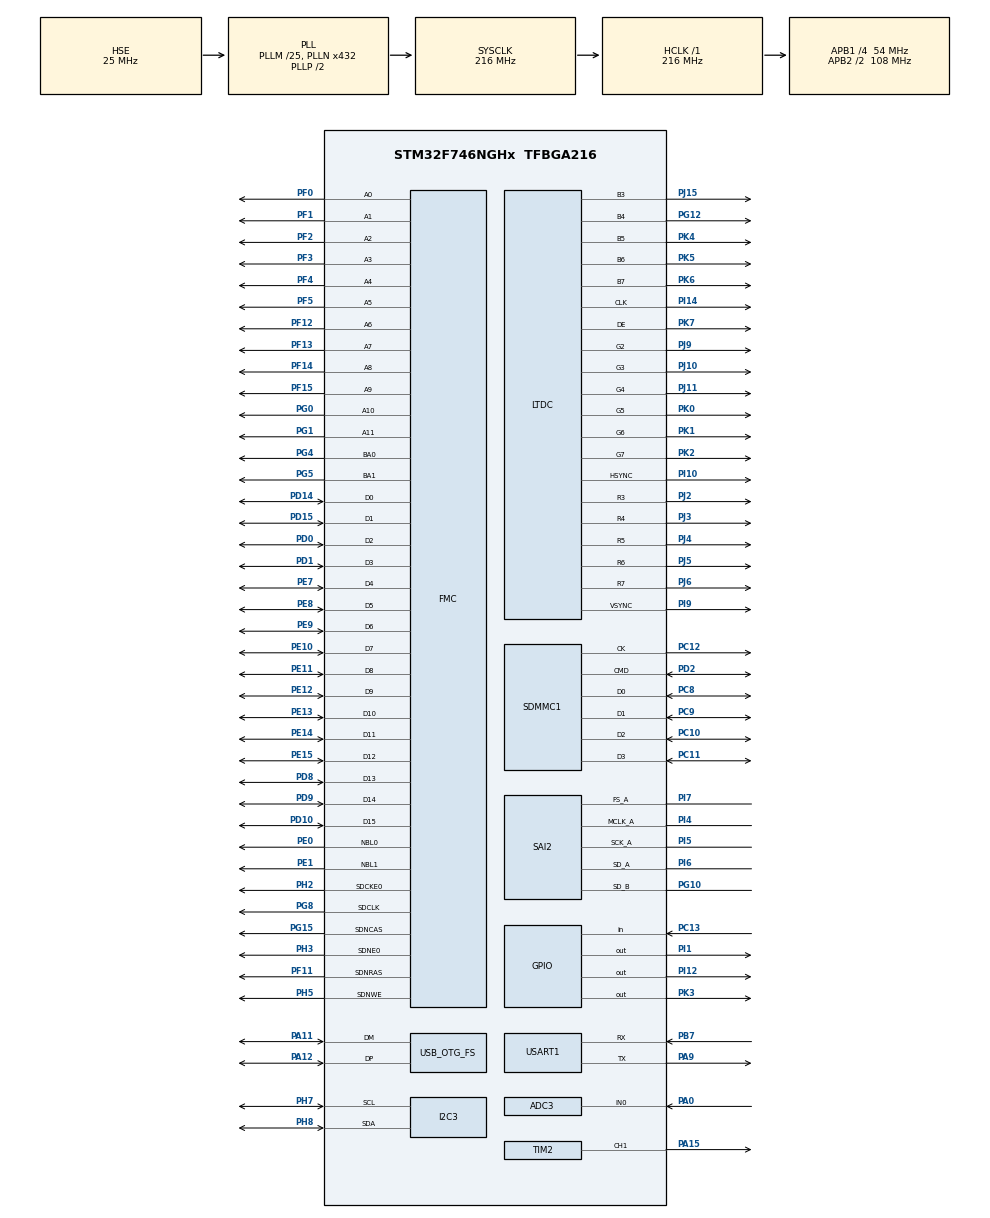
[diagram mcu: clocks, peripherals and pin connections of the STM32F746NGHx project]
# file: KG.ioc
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ADC3.Channel-1\#ChannelRegularConversion=ADC_CHANNEL_0
ADC3.DMAContinuousRequests=ENABLE
ADC3.ExternalTrigConv=ADC_EXTERNALTRIGCONV_T2_CC2
ADC3.NbrOfConversion=1
ADC3.NbrOfConversionFlag=1
ADC3.Rank-1\#ChannelRegularConversion=1
ADC3.SamplingTime-1\#ChannelRegularConversion=ADC_SAMPLETIME_3CYCLES
Dma.ADC3.4.Direction=DMA_PERIPH_TO_MEMORY
Dma.ADC3.4.FIFOMode=DMA_FIFOMODE_DISABLE
Dma.ADC3.4.Instance=DMA2_Stream0
Dma.ADC3.4.MemDataAlignment=DMA_MDATAALIGN_HALFWORD
Dma.ADC3.4.MemInc=DMA_MINC_ENABLE
Dma.ADC3.4.Mode=DMA_CIRCULAR
Dma.ADC3.4.PeriphDataAlignment=DMA_PDATAALIGN_HALFWORD
Dma.ADC3.4.PeriphInc=DMA_PINC_DISABLE
Dma.ADC3.4.Priority=DMA_PRIORITY_LOW
Dma.Request0=SDMMC1_RX
Dma.Request1=SDMMC1_TX
Dma.Request2=SAI2_A
Dma.Request3=SAI2_B
Dma.Request4=ADC3
Dma.SAI2_A.2.Direction=DMA_MEMORY_TO_PERIPH
Dma.SAI2_A.2.FIFOMode=DMA_FIFOMODE_DISABLE
Dma.SAI2_A.2.Instance=DMA2_Stream4
Dma.SAI2_A.2.MemDataAlignment=DMA_MDATAALIGN_HALFWORD
Dma.SAI2_A.2.MemInc=DMA_MINC_ENABLE
Dma.SAI2_A.2.Mode=DMA_CIRCULAR
Dma.SAI2_A.2.PeriphDataAlignment=DMA_PDATAALIGN_HALFWORD
Dma.SAI2_A.2.PeriphInc=DMA_PINC_DISABLE
Dma.SAI2_A.2.Priority=DMA_PRIORITY_LOW
Dma.SAI2_B.3.Direction=DMA_PERIPH_TO_MEMORY
Dma.SAI2_B.3.FIFOMode=DMA_FIFOMODE_DISABLE
Dma.SAI2_B.3.Instance=DMA2_Stream7
Dma.SAI2_B.3.MemDataAlignment=DMA_MDATAALIGN_HALFWORD
Dma.SAI2_B.3.MemInc=DMA_MINC_ENABLE
Dma.SAI2_B.3.Mode=DMA_CIRCULAR
Dma.SAI2_B.3.PeriphDataAlignment=DMA_PDATAALIGN_HALFWORD
Dma.SAI2_B.3.PeriphInc=DMA_PINC_DISABLE
Dma.SAI2_B.3.Priority=DMA_PRIORITY_LOW
Dma.SDMMC1_RX.0.Direction=DMA_PERIPH_TO_MEMORY
Dma.SDMMC1_RX.0.FIFOMode=DMA_FIFOMODE_ENABLE
Dma.SDMMC1_RX.0.FIFOThreshold=DMA_FIFO_THRESHOLD_FULL
Dma.SDMMC1_RX.0.Instance=DMA2_Stream3
Dma.SDMMC1_RX.0.MemBurst=DMA_MBURST_INC4
Dma.SDMMC1_RX.0.MemDataAlignment=DMA_MDATAALIGN_WORD
Dma.SDMMC1_RX.0.MemInc=DMA_MINC_ENABLE
Dma.SDMMC1_RX.0.Mode=DMA_PFCTRL
Dma.SDMMC1_RX.0.PeriphBurst=DMA_PBURST_INC4
Dma.SDMMC1_RX.0.PeriphDataAlignment=DMA_PDATAALIGN_WORD
Dma.SDMMC1_RX.0.PeriphInc=DMA_PINC_DISABLE
Dma.SDMMC1_RX.0.Priority=DMA_PRIORITY_LOW
Dma.SDMMC1_TX.1.Direction=DMA_MEMORY_TO_PERIPH
Dma.SDMMC1_TX.1.FIFOMode=DMA_FIFOMODE_ENABLE
Dma.SDMMC1_TX.1.FIFOThreshold=DMA_FIFO_THRESHOLD_FULL
Dma.SDMMC1_TX.1.Instance=DMA2_Stream6
Dma.SDMMC1_TX.1.MemBurst=DMA_MBURST_INC4
Dma.SDMMC1_TX.1.MemDataAlignment=DMA_MDATAALIGN_WORD
Dma.SDMMC1_TX.1.MemInc=DMA_MINC_ENABLE
Dma.SDMMC1_TX.1.Mode=DMA_PFCTRL
Dma.SDMMC1_TX.1.PeriphBurst=DMA_PBURST_INC4
Dma.SDMMC1_TX.1.PeriphDataAlignment=DMA_PDATAALIGN_WORD
Dma.SDMMC1_TX.1.PeriphInc=DMA_PINC_DISABLE
Dma.SDMMC1_TX.1.Priority=DMA_PRIORITY_LOW
FATFS.BSP.number=1
FATFS.USE_DMA_CODE_SD=1
FATFS._LFN_UNICODE=0
FATFS._STRF_ENCODE=0
FATFS._USE_LFN=0
FATFS0.BSP.STBoard=false
FATFS0.BSP.api=Unknown
FATFS0.BSP.instance=PC13
FATFS0.BSP.ip=GPIO
FATFS0.BSP.mode=Input
FATFS0.BSP.name=Detect_SDIO
FATFS0.BSP.solution=PC13
FMC.CASLatency1=FMC_SDRAM_CAS_LATENCY_3
FMC.ExitSelfRefreshDelay1=7
FMC.LoadToActiveDelay1=2
FMC.RCDDelay1=2
FMC.RPDelay1=2
FMC.RPDelay2=2
FMC.RowCycleDelay1=7
FMC.RowCycleDelay2=7
FMC.SelfRefreshTime1=4
FMC.WriteRecoveryTime1=3
I2C3.Timing=0x20404768
LTDC.ActiveH=272
LTDC.ActiveW=480
LTDC.Alpha_L0=255
LTDC.FBStartAdress_L0=0xC0000000
LTDC.HBP=43
LTDC.HFP=8
LTDC.HSync=1
LTDC.ImageHeight_L0=272
LTDC.ImageWidth_L0=480
LTDC.Layers=0
LTDC.PixelFormat_L0=LTDC_PIXEL_FORMAT_RGB565
LTDC.VBP=12
LTDC.VFP=4
LTDC.VSync=10
LTDC.WindowX1_L0=480
LTDC.WindowY1_L0=272
Mcu.Family=STM32F7
Mcu.Name=STM32F746NGHx
Mcu.Package=TFBGA216
NVIC.DMA2_Stream0_IRQn=true\:0\:0\:false\:false\:true\:false\:true\:true
NVIC.DMA2_Stream3_IRQn=true\:6\:0\:true\:false\:true\:false\:true\:true
NVIC.DMA2_Stream4_IRQn=true\:0\:0\:true\:false\:true\:false\:true\:true
NVIC.DMA2_Stream6_IRQn=true\:6\:0\:true\:false\:true\:false\:true\:true
NVIC.DMA2_Stream7_IRQn=true\:0\:0\:false\:false\:true\:false\:true\:true
NVIC.I2C3_EV_IRQn=true\:0\:0\:false\:false\:true\:true\:true\:true
NVIC.OTG_FS_IRQn=true\:7\:0\:true\:false\:true\:false\:true\:true
NVIC.PriorityGroup=NVIC_PRIORITYGROUP_4
NVIC.SAI2_IRQn=true\:0\:0\:false\:false\:true\:true\:true\:true
NVIC.SDMMC1_IRQn=true\:5\:0\:true\:false\:true\:true\:true\:true
NVIC.USART1_IRQn=true\:0\:0\:false\:false\:true\:true\:true\:true
PA0/WKUP.Signal=ADCx_IN0
PA11.Mode=Device_Only
PA11.Signal=USB_OTG_FS_DM
PA12.Mode=Device_Only
PA12.Signal=USB_OTG_FS_DP
PA13.Mode=Trace_Asynchronous_SW
PA13.Signal=SYS_JTMS-SWDIO
PA14.Mode=Trace_Asynchronous_SW
PA14.Signal=SYS_JTCK-SWCLK
PA15.Signal=S_TIM2_CH1_ETR
PA9.Mode=Asynchronous
PA9.Signal=USART1_TX
PB3.Mode=Trace_Asynchronous_SW
PB3.Signal=SYS_JTDO-SWO
PB7.Mode=Asynchronous
PB7.Signal=USART1_RX
PC10.Mode=SD_4_bits_Wide_bus
PC10.Signal=SDMMC1_D2
PC11.Mode=SD_4_bits_Wide_bus
PC11.Signal=SDMMC1_D3
PC12.Mode=SD_4_bits_Wide_bus
PC12.Signal=SDMMC1_CK
PC13.Signal=GPIO_Input
PC14/OSC32_IN.Mode=LSE-External-Oscillator
PC14/OSC32_IN.Signal=RCC_OSC32_IN
PC15/OSC32_OUT.Mode=LSE-External-Oscillator
PC15/OSC32_OUT.Signal=RCC_OSC32_OUT
PC8.Mode=SD_4_bits_Wide_bus
PC8.Signal=SDMMC1_D0
PC9.Mode=SD_4_bits_Wide_bus
PC9.Signal=SDMMC1_D1
PD0.Signal=FMC_D2_DA2
PD1.Signal=FMC_D3_DA3
PD10.Signal=FMC_D15_DA15
PD14.Signal=FMC_D0_DA0
PD15.Signal=FMC_D1_DA1
PD2.Mode=SD_4_bits_Wide_bus
PD2.Signal=SDMMC1_CMD
PD8.Signal=FMC_D13_DA13
PD9.Signal=FMC_D14_DA14
PE0.Signal=FMC_NBL0
PE1.Signal=FMC_NBL1
PE10.Signal=FMC_D7_DA7
PE11.Signal=FMC_D8_DA8
PE12.Signal=FMC_D9_DA9
PE13.Signal=FMC_D10_DA10
PE14.Signal=FMC_D11_DA11
PE15.Signal=FMC_D12_DA12
PE7.Signal=FMC_D4_DA4
PE8.Signal=FMC_D5_DA5
PE9.Signal=FMC_D6_DA6
PF0.Signal=FMC_A0
PF1.Signal=FMC_A1
PF11.Signal=FMC_SDNRAS
PF12.Signal=FMC_A6
PF13.Signal=FMC_A7
PF14.Signal=FMC_A8
PF15.Signal=FMC_A9
PF2.Signal=FMC_A2
PF3.Signal=FMC_A3
PF4.Signal=FMC_A4
PF5.Signal=FMC_A5
PG0.Signal=FMC_A10
PG1.Signal=FMC_A11
PG10.Mode=SAI_B_SyncSlave
PG10.Signal=SAI2_SD_B
PG12.Mode=RGB565
PG12.Signal=LTDC_B4
PG15.Signal=FMC_SDNCAS
PG4.Signal=FMC_A14_BA0
PG5.Signal=FMC_A15_BA1
PG8.Signal=FMC_SDCLK
PH0/OSC_IN.Mode=HSE-External-Oscillator
PH0/OSC_IN.Signal=RCC_OSC_IN
PH1/OSC_OUT.Mode=HSE-External-Oscillator
PH1/OSC_OUT.Signal=RCC_OSC_OUT
PH2.Mode=SdramChipSelect1_1
PH2.Signal=FMC_SDCKE0
PH3.Mode=SdramChipSelect1_1
PH3.Signal=FMC_SDNE0
PH5.Signal=FMC_SDNWE
PH7.Mode=I2C
PH7.Signal=I2C3_SCL
PH8.Mode=I2C
PH8.Signal=I2C3_SDA
PI1.Signal=GPIO_Output
PI10.Mode=RGB565
PI10.Signal=LTDC_HSYNC
PI12.PinState=GPIO_PIN_SET
PI12.Signal=GPIO_Output
PI14.Mode=RGB565
PI14.Signal=LTDC_CLK
PI4.Mode=SAI_A_MasterWithClock
PI4.Signal=SAI2_MCLK_A
PI5.Mode=SAI_A_MasterWithClock
PI5.Signal=SAI2_SCK_A
PI6.Mode=SAI_A_MasterWithClock
PI6.Signal=SAI2_SD_A
PI7.Mode=SAI_A_MasterWithClock
PI7.Signal=SAI2_FS_A
PI9.Mode=RGB565
PI9.Signal=LTDC_VSYNC
PJ10.Mode=RGB565
PJ10.Signal=LTDC_G3
PJ11.Mode=RGB565
PJ11.Signal=LTDC_G4
PJ15.Mode=RGB565
PJ15.Signal=LTDC_B3
PJ2.Mode=RGB565
PJ2.Signal=LTDC_R3
PJ3.Mode=RGB565
PJ3.Signal=LTDC_R4
PJ4.Mode=RGB565
PJ4.Signal=LTDC_R5
PJ5.Mode=RGB565
PJ5.Signal=LTDC_R6
PJ6.Mode=RGB565
PJ6.Signal=LTDC_R7
PJ9.Mode=RGB565
PJ9.Signal=LTDC_G2
PK0.Mode=RGB565
PK0.Signal=LTDC_G5
PK1.Mode=RGB565
PK1.Signal=LTDC_G6
PK2.Mode=RGB565
PK2.Signal=LTDC_G7
PK3.PinState=GPIO_PIN_SET
PK3.Signal=GPIO_Output
PK4.Mode=RGB565
PK4.Signal=LTDC_B5
PK5.Mode=RGB565
PK5.Signal=LTDC_B6
PK6.Mode=RGB565
PK6.Signal=LTDC_B7
PK7.Mode=RGB565
PK7.Signal=LTDC_DE
ProjectManager.HeapSize=0x1000
ProjectManager.StackSize=0x1000
ProjectManager.TargetToolchain=MDK-ARM V5.32
RCC.AHBFreq_Value=216000000
RCC.APB1CLKDivider=RCC_HCLK_DIV4
RCC.APB1Freq_Value=54000000
RCC.APB1TimFreq_Value=108000000
RCC.APB2CLKDivider=RCC_HCLK_DIV2
RCC.APB2Freq_Value=108000000
RCC.APB2TimFreq_Value=216000000
RCC.CortexFreq_Value=216000000
RCC.HCLKFreq_Value=216000000
RCC.HSE_VALUE=25000000
RCC.HSI_VALUE=16000000
RCC.PLLI2SN=344
RCC.PLLI2SQ=7
RCC.PLLM=25
RCC.PLLN=432
RCC.PLLQ=9
RCC.PLLSAIN=200
RCC.PLLSAIR=5
RCC.PLLSAIRDiv=RCC_PLLSAIDIVR_4
RCC.RTCClockSelection=RCC_RTCCLKSOURCE_LSE
RCC.SAI2CLockSelection=RCC_SAI2CLKSOURCE_PLLI2S
RCC.SDMMCClockSelection=RCC_SDMMC1CLKSOURCE_CLK48
RCC.SYSCLKFreq_VALUE=216000000
RCC.SYSCLKSource=RCC_SYSCLKSOURCE_PLLCLK
RCC.USBFreq_Value=48000000
RCC.VCOOutputFreq_Value=432000000
RTC.Date=17
RTC.Hours=12
RTC.Minutes=4
RTC.Month=RTC_MONTH_OCTOBER
RTC.Seconds=33
RTC.Year=22
SAI2.ActiveFrameLength-SAI_A_MasterWithClock=32
SAI2.ActiveFrameLength-SAI_B_SyncSlave=32
SAI2.AudioFrequency-SAI_A_MasterWithClock=SAI_AUDIO_FREQUENCY_48K
SAI2.ClockStrobing-SAI_A_MasterWithClock=SAI_CLOCKSTROBING_RISINGEDGE
SAI2.DataSize-SAI_A_MasterWithClock=SAI_DATASIZE_16
SAI2.DataSize-SAI_B_SyncSlave=SAI_DATASIZE_16
SAI2.ErrorAudioFreq-SAI_A_MasterWithClock=-0.01 %
SAI2.FIFOThreshold-SAI_A_MasterWithClock=SAI_FIFOTHRESHOLD_1QF
SAI2.FIFOThreshold-SAI_B_SyncSlave=SAI_FIFOTHRESHOLD_1QF
SAI2.FSDefinition-SAI_A_MasterWithClock=SAI_FS_CHANNEL_IDENTIFICATION
SAI2.FSDefinition-SAI_B_SyncSlave=SAI_FS_CHANNEL_IDENTIFICATION
SAI2.FrameLength-SAI_A_MasterWithClock=64
SAI2.FrameLength-SAI_B_SyncSlave=64
SAI2.Instance-SAI_A_MasterWithClock=SAI$Index_Block_A
SAI2.Instance-SAI_B_SyncSlave=SAI$Index_Block_B
SAI2.MClockEnable-SAI_A_MasterWithClock=SAI_MASTERCLOCK_ENABLE
SAI2.RealAudioFreq-SAI_A_MasterWithClock=47.991 KHz
SAI2.SlotActive-SAI_A_MasterWithClock=0x0000FFFF
SAI2.SlotActive-SAI_B_SyncSlave=0x0000FFFF
SAI2.SlotNumber-SAI_A_MasterWithClock=4
SAI2.SlotNumber-SAI_B_SyncSlave=4
SAI2.VirtualMode-SAI_A_MasterWithClock=VM_MASTER
SAI2.VirtualMode-SAI_B_SyncSlave=VM_SLAVE
SAI2.VirtualSlotActive-SAI_A_MasterWithClock=SAI_SLOTACTIVE_ALL
SAI2.VirtualSlotActive-SAI_B_SyncSlave=SAI_SLOTACTIVE_ALL
SDMMC1.HardwareFlowControl=SDMMC_HARDWARE_FLOW_CONTROL_ENABLE
SH.ADCx_IN0.0=ADC3_IN0,IN0
SH.FMC_A0.0=FMC_A0,12b-sda1
SH.FMC_A1.0=FMC_A1,12b-sda1
SH.FMC_A10.0=FMC_A10,12b-sda1
SH.FMC_A11.0=FMC_A11,12b-sda1
SH.FMC_A14_BA0.0=FMC_BA0,FourSdramBanks1
SH.FMC_A15_BA1.0=FMC_BA1,FourSdramBanks1
SH.FMC_A2.0=FMC_A2,12b-sda1
SH.FMC_A3.0=FMC_A3,12b-sda1
SH.FMC_A4.0=FMC_A4,12b-sda1
SH.FMC_A5.0=FMC_A5,12b-sda1
SH.FMC_A6.0=FMC_A6,12b-sda1
SH.FMC_A7.0=FMC_A7,12b-sda1
SH.FMC_A8.0=FMC_A8,12b-sda1
SH.FMC_A9.0=FMC_A9,12b-sda1
SH.FMC_D0_DA0.0=FMC_D0,sd-16b-d1
SH.FMC_D10_DA10.0=FMC_D10,sd-16b-d1
SH.FMC_D11_DA11.0=FMC_D11,sd-16b-d1
SH.FMC_D12_DA12.0=FMC_D12,sd-16b-d1
SH.FMC_D13_DA13.0=FMC_D13,sd-16b-d1
SH.FMC_D14_DA14.0=FMC_D14,sd-16b-d1
SH.FMC_D15_DA15.0=FMC_D15,sd-16b-d1
SH.FMC_D1_DA1.0=FMC_D1,sd-16b-d1
SH.FMC_D2_DA2.0=FMC_D2,sd-16b-d1
SH.FMC_D3_DA3.0=FMC_D3,sd-16b-d1
SH.FMC_D4_DA4.0=FMC_D4,sd-16b-d1
SH.FMC_D5_DA5.0=FMC_D5,sd-16b-d1
SH.FMC_D6_DA6.0=FMC_D6,sd-16b-d1
SH.FMC_D7_DA7.0=FMC_D7,sd-16b-d1
SH.FMC_D8_DA8.0=FMC_D8,sd-16b-d1
SH.FMC_D9_DA9.0=FMC_D9,sd-16b-d1
SH.FMC_NBL0.0=FMC_NBL0,Sd2ByteEnable1
SH.FMC_NBL1.0=FMC_NBL1,Sd2ByteEnable1
SH.FMC_SDCLK.0=FMC_SDCLK,12b-sda1
SH.FMC_SDNCAS.0=FMC_SDNCAS,12b-sda1
SH.FMC_SDNRAS.0=FMC_SDNRAS,12b-sda1
SH.FMC_SDNWE.0=FMC_SDNWE,12b-sda1
SH.S_TIM2_CH1_ETR.0=TIM2_CH1,PWM Generation1 CH1
TIM2.Channel-PWM\ Generation1\ CH1=TIM_CHANNEL_1
TIM2.Channel-PWM\ Generation2\ No\ Output=TIM_CHANNEL_2
TIM2.Period=75-1
TIM2.Prescaler=3-1
TIM2.Pulse-PWM\ Generation1\ CH1=1
TIM2.Pulse-PWM\ Generation2\ No\ Output=37
USART1.VirtualMode-Asynchronous=VM_ASYNC
USB_DEVICE.CLASS_NAME_FS=MSC
USB_DEVICE.VirtualMode-MSC_FS=Msc
USB_DEVICE.VirtualModeFS=Msc_FS
USB_OTG_FS.VirtualMode=Device_Only
VP_FATFS_VS_SDIO.Mode=SDIO
VP_RTC_VS_RTC_Activate.Mode=RTC_Enabled
VP_RTC_VS_RTC_Calendar.Mode=RTC_Calendar
VP_TIM2_VS_ClockSourceINT.Mode=Internal
VP_TIM2_VS_no_output2.Mode=PWM Generation2 No Output
VP_USB_DEVICE_VS_USB_DEVICE_MSC_FS.Mode=MSC_FS
board=custom

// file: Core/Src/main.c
/* USER CODE BEGIN Header */
/**
  ******************************************************************************
  * @file           : main.c
  * @brief          : Main program body
  ******************************************************************************
  * @attention
  *
  * Copyright (c) 2022 STMicroelectronics.
  * All rights reserved.
  *
  * This software is licensed under terms that can be found in the LICENSE file
  * in the root directory of this software component.
  * If no LICENSE file comes with this software, it is provided AS-IS.
  *
  ******************************************************************************
  */
/* USER CODE END Header */
#include "main.h"
#include "adc.h"
#include "dma.h"
#include "fatfs.h"
#include "i2c.h"
#include "ltdc.h"
#include "rtc.h"
#include "sai.h"
#include "sdmmc.h"
#include "tim.h"
#include "usart.h"
#include "usb_device.h"
#include "gpio.h"
#include "fmc.h"

/* USER CODE BEGIN Includes */

#include "lv_port_disp.h"
#include "ui.h"
#include "lv_port_indev.h"
#include "recorder.h"
#include "clock.h"
/* USER CODE END Includes */

/* USER CODE BEGIN PV */
RTC_TimeTypeDef sysTime;
RTC_DateTypeDef sysDate;
uint32_t DMA_Buffer[30];
uint16_t lcd_disp_buf[480*272] __attribute__((section(".ARM.__at_0xC0000000")));

AUDIO_ApplicationTypeDef appli_state = APPLICATION_IDLE;

//char str1[16]={0};

/* USER CODE END PV */

void SystemClock_Config(void);
void PeriphCommonClock_Config(void);

/* USER CODE BEGIN 0 */

void HAL_ADC_ConvCpltCallback(ADC_HandleTypeDef* hadc)
{
  ;
}

/* USER CODE END 0 */

int main(void)
{

  /* MCU Configuration--------------------------------------------------------*/

  /* Reset of all peripherals, Initializes the Flash interface and the Systick. */
  HAL_Init();

  /* Configure the system clock */
  SystemClock_Config();

/* Configure the peripherals common clocks */
  PeriphCommonClock_Config();

  /* Initialize all configured peripherals */
  MX_GPIO_Init();
  MX_LTDC_Init();
  MX_TIM2_Init();
  MX_I2C3_Init();
  MX_SDMMC1_SD_Init();
  MX_DMA_Init();
  MX_FATFS_Init();
  MX_USB_DEVICE_Init();
  MX_SAI2_Init();
  MX_USART1_UART_Init();
  MX_RTC_Init();
  MX_FMC_Init();
  MX_ADC3_Init();
  /* USER CODE BEGIN 2 */

  BSP_SDRAM_Init();
  HAL_ADC_Start_DMA(&hadc3, DMA_Buffer, 30);
  HAL_TIM_PWM_Start(&htim2, TIM_CHANNEL_1);
  HAL_TIM_PWM_Start(&htim2, TIM_CHANNEL_2);

  FATFS_LinkDriver(&SD_Driver, SDPath);
  retSD = f_mount(&SDFatFS,"",1);
  if(retSD == FR_OK)
  {
    appli_state = APPLICATION_READY;
  }
  else
  {
    printf("FatFs Initialization Failed\n");
    while(1);
  }
//  if (retSD == FR_NO_FILESYSTEM)
//  {
//    retSD = f_mkfs("0:",0,0);
//    if(retSD== FR_OK)
//    {
//      retSD = f_mount(NULL, )
//    }
//  }
  /**
  if(retSD == FR_OK)
  {
      printf("mount OK\n");
      retSD = f_open(&SDFile, "test.txt", FA_CREATE_ALWAYS | FA_WRITE);
      if(retSD == FR_OK)
      {
          printf("open OK\n");
          retSD = f_printf(&SDFile, "hello, world\n");
          printf("write ret:%d\n",retSD);
      }
      retSD = f_close(&SDFile);
      printf("close ret:%d\n",retSD);
  }
  **/

  lv_init();
  lv_port_disp_init();
  lv_port_indev_init();
  ui_init();
  ui_Clock_Start();

  //HAL_RTC_GetTime(&hrtc, &sysTime, RTC_FORMAT_BIN);
  //HAL_RTC_GetDate(&hrtc, &sysDate, RTC_FORMAT_BIN);
  //printf("%02d:%02d:%02d\n",sysTime.Hours, sysTime.Minutes, sysTime.Seconds);

  AUDIO_Init();

  /* USER CODE END 2 */

  /* Infinite loop */
    while (1)
    {

    /* USER CODE BEGIN 3 */
//       if(0 == displayFlag)
//        {
//            lv_chart_refresh(ui_Chart1);
//            displayFlag=1;
//        }
        lv_task_handler();
        AUDIO_StateMachineProcess();

        //lv_textarea_set_text(ui_VoltMeter, str1);
    }
  /* USER CODE END 3 */
}

void SystemClock_Config(void)
{
  RCC_OscInitTypeDef RCC_OscInitStruct = {0};
  RCC_ClkInitTypeDef RCC_ClkInitStruct = {0};

  /** Configure LSE Drive Capability
  */
  HAL_PWR_EnableBkUpAccess();
  __HAL_RCC_LSEDRIVE_CONFIG(RCC_LSEDRIVE_LOW);

  /** Configure the main internal regulator output voltage
  */
  __HAL_RCC_PWR_CLK_ENABLE();
  __HAL_PWR_VOLTAGESCALING_CONFIG(PWR_REGULATOR_VOLTAGE_SCALE1);

  /** Initializes the RCC Oscillators according to the specified parameters
  * in the RCC_OscInitTypeDef structure.
  */
  RCC_OscInitStruct.OscillatorType = RCC_OSCILLATORTYPE_HSE|RCC_OSCILLATORTYPE_LSE;
  RCC_OscInitStruct.HSEState = RCC_HSE_ON;
  RCC_OscInitStruct.LSEState = RCC_LSE_ON;
  RCC_OscInitStruct.PLL.PLLState = RCC_PLL_ON;
  RCC_OscInitStruct.PLL.PLLSource = RCC_PLLSOURCE_HSE;
  RCC_OscInitStruct.PLL.PLLM = 25;
  RCC_OscInitStruct.PLL.PLLN = 432;
  RCC_OscInitStruct.PLL.PLLP = RCC_PLLP_DIV2;
  RCC_OscInitStruct.PLL.PLLQ = 9;
  if (HAL_RCC_OscConfig(&RCC_OscInitStruct) != HAL_OK)
  {
    Error_Handler();
  }

  /** Activate the Over-Drive mode
  */
  if (HAL_PWREx_EnableOverDrive() != HAL_OK)
  {
    Error_Handler();
  }

  /** Initializes the CPU, AHB and APB buses clocks
  */
  RCC_ClkInitStruct.ClockType = RCC_CLOCKTYPE_HCLK|RCC_CLOCKTYPE_SYSCLK
                              |RCC_CLOCKTYPE_PCLK1|RCC_CLOCKTYPE_PCLK2;
  RCC_ClkInitStruct.SYSCLKSource = RCC_SYSCLKSOURCE_PLLCLK;
  RCC_ClkInitStruct.AHBCLKDivider = RCC_SYSCLK_DIV1;
  RCC_ClkInitStruct.APB1CLKDivider = RCC_HCLK_DIV4;
  RCC_ClkInitStruct.APB2CLKDivider = RCC_HCLK_DIV2;

  if (HAL_RCC_ClockConfig(&RCC_ClkInitStruct, FLASH_LATENCY_7) != HAL_OK)
  {
    Error_Handler();
  }
}

void PeriphCommonClock_Config(void)
{
  RCC_PeriphCLKInitTypeDef PeriphClkInitStruct = {0};

  /** Initializes the peripherals clock
  */
  PeriphClkInitStruct.PeriphClockSelection = RCC_PERIPHCLK_SAI2;
  PeriphClkInitStruct.PLLI2S.PLLI2SN = 344;
  PeriphClkInitStruct.PLLI2S.PLLI2SP = RCC_PLLP_DIV2;
  PeriphClkInitStruct.PLLI2S.PLLI2SR = 2;
  PeriphClkInitStruct.PLLI2S.PLLI2SQ = 7;
  PeriphClkInitStruct.PLLI2SDivQ = 1;
  PeriphClkInitStruct.Sai2ClockSelection = RCC_SAI2CLKSOURCE_PLLI2S;
  if (HAL_RCCEx_PeriphCLKConfig(&PeriphClkInitStruct) != HAL_OK)
  {
    Error_Handler();
  }
}

void Error_Handler(void)
{
  __disable_irq();
  while (1)
  {
  }
}
